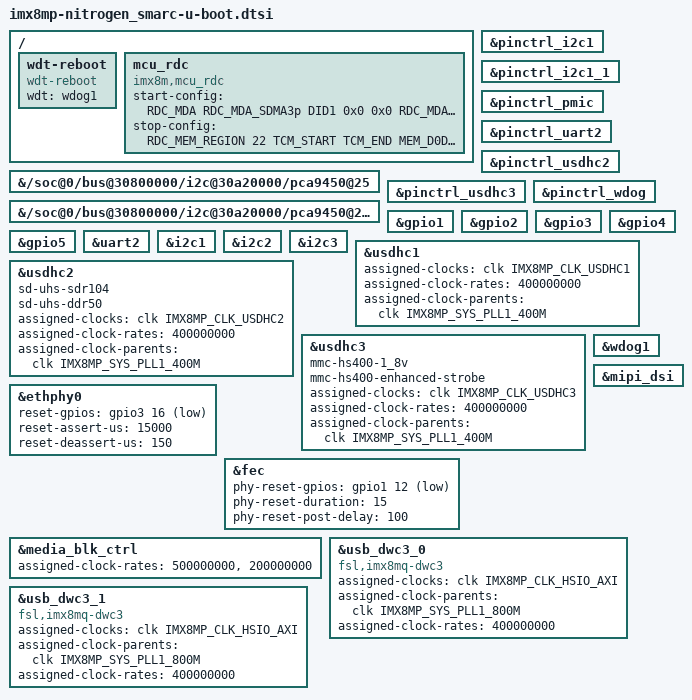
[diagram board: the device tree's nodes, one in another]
// SPDX-License-Identifier: GPL-2.0+
/*
 * Copyright 2025 Ezurio
 */
#include "imx8mp-sec-def.h"

#include "imx8mp-u-boot.dtsi"

/ {
	wdt-reboot {
		compatible = "wdt-reboot";
		wdt = <&wdog1>;
		bootph-pre-ram;
	};

	mcu_rdc {
		compatible = "imx8m,mcu_rdc";
			    /* rdc config when MCU starts
			     * master
			     *   SDMA3p --> domain 1
			     *   SDMA3b --> domian 1
			     *   SDMA3_SPBA2  --> domian 1
			     * peripheral:
			     *   SAI3   --> Only Domian 1 can access
			     *   UART4  --> Only Domian 1 can access
			     *   GPT1   --> Only Domian 1 can access
			     *   SDMA3  --> Only Domian 1 can access
			     *   I2C3   --> Only Domian 1 can access
			     * memory:
			     *   TCM    --> Only Domian 1 can access (0x7E0000~0x81FFFF)
			     *   DDR    --> Only Domian 1 can access (0x80000000~0x81000000)
			     * end.
			     */
		start-config = <
			    RDC_MDA  RDC_MDA_SDMA3p DID1 0x0 0x0
			    RDC_MDA  RDC_MDA_ENET1_TX DID1 0x0 0x0
			    RDC_MDA  RDC_MDA_ENET1_RX DID1 0x0 0x0
			    RDC_MDA  RDC_MDA_SDMA3b DID1 0x0 0x0
			    RDC_MDA  RDC_MDA_SDMA3_SPBA2 DID1 0x0 0x0
			    RDC_PDAP RDC_PDAP_ENET1 PDAP_D0D1_ACCESS 0x0 0x0
			    RDC_PDAP RDC_PDAP_SAI3  PDAP_D1_ACCESS 0x0 0x0
			    RDC_PDAP RDC_PDAP_UART4 PDAP_D1_ACCESS 0x0 0x0
			    RDC_PDAP RDC_PDAP_GPT1  PDAP_D1_ACCESS 0x0 0x0
			    RDC_PDAP RDC_PDAP_SDMA3 PDAP_D1_ACCESS 0x0 0x0
			    RDC_PDAP RDC_PDAP_I2C3  PDAP_D1_ACCESS 0x0 0x0
			    RDC_MEM_REGION 22 TCM_START TCM_END MEM_D1_ACCESS
			    RDC_MEM_REGION 39 M4_DDR_START M4_DDR_END MEM_D1_ACCESS
			    0x0      0x0            0x0  0x0 0x0
			  >;
			    /* rdc config when MCU stops
			     * memory:
			     *   TCM    --> domain 0/1 can access (0x7E0000~0x81FFFF)
			     *   DDR    --> domain 0/1 can access (0x80000000~0x81000000)
			     * end.
			     */
		stop-config = <
			    RDC_MEM_REGION 22 TCM_START TCM_END MEM_D0D1_ACCESS
			    RDC_MEM_REGION 39 M4_DDR_START M4_DDR_END MEM_D0D1_ACCESS
			    0x0      0x0            0x0  0x0 0x0
			  >;
	};
};

&pinctrl_i2c1 {
	bootph-all;
};

&pinctrl_i2c1_1 {
	bootph-all;
};

&pinctrl_pmic {
	bootph-all;
};

&{/soc@0/bus@30800000/i2c@30a20000/pca9450@25} {
	bootph-all;
};

&{/soc@0/bus@30800000/i2c@30a20000/pca9450@25/regulators} {
	bootph-all;
};

&pinctrl_uart2 {
	bootph-pre-ram;
};

&pinctrl_usdhc2 {
	bootph-pre-ram;
};

&pinctrl_usdhc3 {
	bootph-pre-ram;
};

&pinctrl_wdog {
	bootph-pre-ram;
};

&gpio1 {
	bootph-pre-ram;
};

&gpio2 {
	bootph-pre-ram;
};

&gpio3 {
	bootph-pre-ram;
};

&gpio4 {
	bootph-pre-ram;
};

&gpio5 {
	bootph-pre-ram;
};

&uart2 {
	bootph-pre-ram;
};

&i2c1 {
	bootph-all;
};

&i2c2 {
	bootph-pre-ram;
};

&i2c3 {
	bootph-pre-ram;
};

&usdhc1 {
	bootph-pre-ram;
	assigned-clocks = <&clk IMX8MP_CLK_USDHC1>;
	assigned-clock-rates = <400000000>;
	assigned-clock-parents = <&clk IMX8MP_SYS_PLL1_400M>;
};

&usdhc2 {
	bootph-pre-ram;
	sd-uhs-sdr104;
	sd-uhs-ddr50;
	assigned-clocks = <&clk IMX8MP_CLK_USDHC2>;
	assigned-clock-rates = <400000000>;
	assigned-clock-parents = <&clk IMX8MP_SYS_PLL1_400M>;
};

&usdhc3 {
	bootph-pre-ram;
	mmc-hs400-1_8v;
	mmc-hs400-enhanced-strobe;
	assigned-clocks = <&clk IMX8MP_CLK_USDHC3>;
	assigned-clock-rates = <400000000>;
	assigned-clock-parents = <&clk IMX8MP_SYS_PLL1_400M>;
};

&wdog1 {
	bootph-pre-ram;
};

&ethphy0 {
	reset-gpios = <&gpio3 16 GPIO_ACTIVE_LOW>;
	reset-assert-us = <15000>;
	reset-deassert-us = <150>;
};

&fec {
	phy-reset-gpios = <&gpio1 12 GPIO_ACTIVE_LOW>;
	phy-reset-duration = <15>;
	phy-reset-post-delay = <100>;
};

&mipi_dsi {
	/delete-property/ assigned-clocks;
	/delete-property/ assigned-clock-parents;
	/delete-property/ assigned-clock-rates;
};

&media_blk_ctrl {
	assigned-clock-rates = <500000000>, <200000000>;
};

&usb_dwc3_0 {
	compatible = "fsl,imx8mq-dwc3", "snps,dwc3";
	assigned-clocks = <&clk IMX8MP_CLK_HSIO_AXI>;
	assigned-clock-parents = <&clk IMX8MP_SYS_PLL1_800M>;
	assigned-clock-rates = <400000000>;
};

&usb_dwc3_1 {
	compatible = "fsl,imx8mq-dwc3", "snps,dwc3";
	assigned-clocks = <&clk IMX8MP_CLK_HSIO_AXI>;
	assigned-clock-parents = <&clk IMX8MP_SYS_PLL1_800M>;
	assigned-clock-rates = <400000000>;
};
